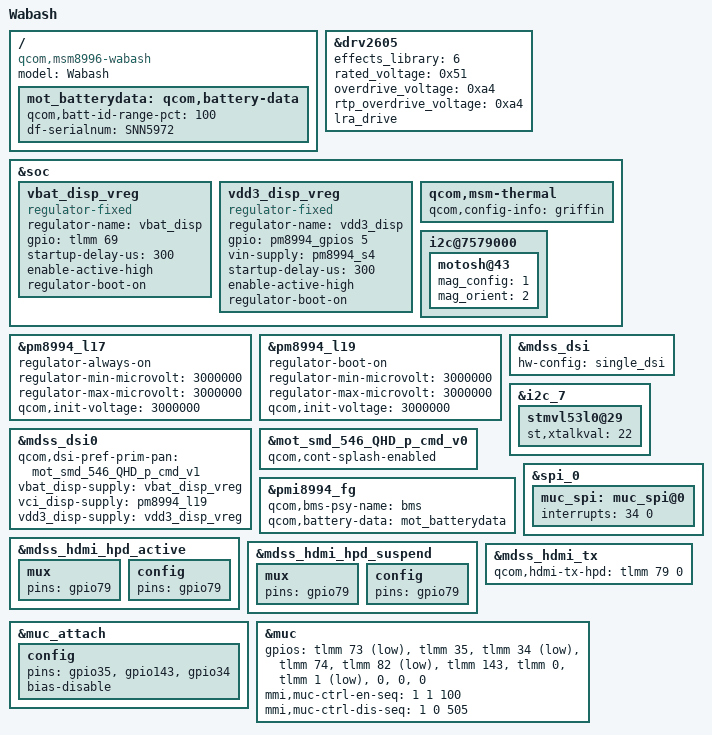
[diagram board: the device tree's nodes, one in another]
/* Copyright (c) 2016, Motorla Mobility LLC. All rights reserved.
 *
 * This program is free software; you can redistribute it and/or modify
 * it under the terms of the GNU General Public License version 2 and
 * only version 2 as published by the Free Software Foundation.
 *
 * This program is distributed in the hope that it will be useful,
 * but WITHOUT ANY WARRANTY; without even the implied warranty of
 * MERCHANTABILITY or FITNESS FOR A PARTICULAR PURPOSE.  See the
 * GNU General Public License for more details.
 */

#include "msm8996-moto-common.dtsi"
#include "dsi-panel-mot-smd-546-QHD-p-cmd.dtsi"

/ {
	model = "Wabash";
	compatible = "qcom,msm8996-wabash", "qcom,msm8996-moto",
			"qcom,msm8996";
};

&drv2605 {
	effects_library = <6>;
	rated_voltage = <0x51>;
	overdrive_voltage = <0xa4>;
	rtp_overdrive_voltage = <0xa4>;
	lra_drive;
};

&soc {
	vbat_disp_vreg: vbat_disp_vreg {
		compatible = "regulator-fixed";
		regulator-name = "vbat_disp";
		gpio = <&tlmm 69 0>;
		startup-delay-us = <300>;
		enable-active-high;
		regulator-boot-on;
	};

	vdd3_disp_vreg: vdd3_disp_vreg {
		compatible = "regulator-fixed";
		regulator-name = "vdd3_disp";
		gpio = <&pm8994_gpios 5 0>;
		vin-supply = <&pm8994_s4>;
		startup-delay-us = <300>;
		enable-active-high;
		regulator-boot-on;
	};

	qcom,msm-thermal {
		qcom,config-info = "griffin";
	};

	/* SensorHub Bus */
	i2c@7579000 {
		motosh@43 {
			mag_config = <1>;     /* Magnetometer config value */
			mag_orient = <2>;     /* Mag Orientation value */
		};
	};
};

&pm8994_l17 {
	regulator-always-on;
	regulator-min-microvolt = <3000000>;
	regulator-max-microvolt = <3000000>;
	qcom,init-voltage = <3000000>;
};

&pm8994_l19 {
	regulator-boot-on;
	regulator-min-microvolt = <3000000>;
	regulator-max-microvolt = <3000000>;
	qcom,init-voltage = <3000000>;
};

&mdss_dsi {
	hw-config = "single_dsi";
};

&mdss_dsi0 {
	qcom,dsi-pref-prim-pan = <&mot_smd_546_QHD_p_cmd_v1>;
	vbat_disp-supply = <&vbat_disp_vreg>;
	vci_disp-supply = <&pm8994_l19>;
	vdd3_disp-supply = <&vdd3_disp_vreg>;
};

&mot_smd_546_QHD_p_cmd_v0 {
	qcom,cont-splash-enabled;
};

&i2c_7 {
	stmvl53l0@29 {
		st,xtalkval = <22>;
	};
};

/{
	mot_batterydata: qcom,battery-data {
		qcom,batt-id-range-pct = <100>;
		df-serialnum = "SNN5972";

		#include "batterydata-gv30-lg.dtsi"
	};
};

&pmi8994_fg {
	qcom,bms-psy-name = "bms";
	/delete-property/ qcom,ext-sense-type; /* External Sense Resistor */
	qcom,battery-data = <&mot_batterydata>;
};

&spi_0 {
	muc_spi: muc_spi@0 {
		interrupts = <34 0>;
	};
};

&mdss_hdmi_hpd_active {
	mux {
		pins = "gpio79";
	};

	config {
		pins = "gpio79";
	};
};

&mdss_hdmi_hpd_suspend {
	mux {
		pins = "gpio79";
	};

	config {
		pins = "gpio79";
	};
};

&mdss_hdmi_tx {
	qcom,hdmi-tx-hpd = <&tlmm 79 0>;
};

&muc_attach {
	config {
		pins = "gpio35", "gpio143", "gpio34";
		bias-disable;
	};
};

&muc {
	gpios = <&tlmm 73 1>,   /* gpio_muc_det_n,    input */
		<&tlmm 35 0>,   /* gpio_muc_bplus_en, output-low */
		<&tlmm 34 1>,   /* gpio_muc_int_n,    input */
		<&tlmm 74 2>,   /* gpio_muc_wake_n,   output-high */
		<&tlmm 82 1>,   /* gpio_muc_rdy_n,    input */
		<&tlmm 143 0>,  /* gpio_muc_ff,       output-low */
		<&tlmm 0 0>,    /* gpio_muc_spi_mosi, output-low */
		<&tlmm 1 1>,    /* gpio_muc_spi_miso, input */
		<0>,            /* gpio_muc_bplus_iset, cs */
		<0>,            /* gpio_muc_bplus_discharg, cs */
		<0>;            /* gpio_muc_bplus_fault_n, unused */

	mmi,muc-ctrl-en-seq =  <1 1 100>;
	mmi,muc-ctrl-dis-seq = <1 0 505>;
};
